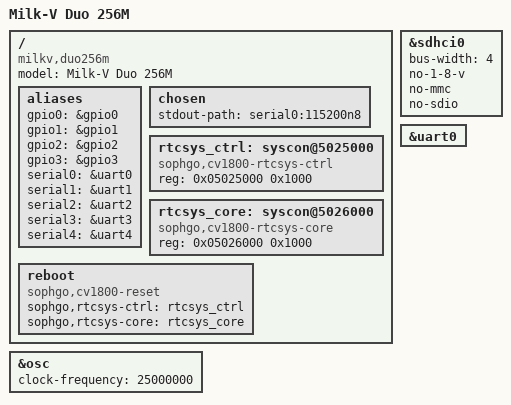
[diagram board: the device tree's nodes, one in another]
// SPDX-License-Identifier: (GPL-2.0 OR MIT)
/*
 * OpenSBI DT for the Milk-V Duo 256M.
 *
 * Base SoC content comes from upstream Linux DTS sources vendored under
 * board/kernel-upstream.
 */

/dts-v1/;

#include "sg2002.dtsi"

/ {
	model = "Milk-V Duo 256M";
	compatible = "milkv,duo256m", "sophgo,sg2002";

	aliases {
		gpio0 = &gpio0;
		gpio1 = &gpio1;
		gpio2 = &gpio2;
		gpio3 = &gpio3;
		serial0 = &uart0;
		serial1 = &uart1;
		serial2 = &uart2;
		serial3 = &uart3;
		serial4 = &uart4;
	};

	chosen {
		stdout-path = "serial0:115200n8";
	};

	rtcsys_ctrl: syscon@5025000 {
		compatible = "sophgo,cv1800-rtcsys-ctrl", "syscon";
		reg = <0x05025000 0x1000>;
	};

	rtcsys_core: syscon@5026000 {
		compatible = "sophgo,cv1800-rtcsys-core", "syscon";
		reg = <0x05026000 0x1000>;
	};

	reboot {
		compatible = "sophgo,cv1800-reset";
		sophgo,rtcsys-ctrl = <&rtcsys_ctrl>;
		sophgo,rtcsys-core = <&rtcsys_core>;
	};
};

&osc {
	clock-frequency = <25000000>;
};

&sdhci0 {
	status = "okay";
	bus-width = <4>;
	no-1-8-v;
	no-mmc;
	no-sdio;
};

&uart0 {
	status = "okay";
};
